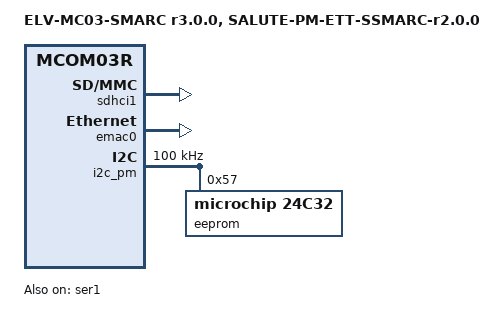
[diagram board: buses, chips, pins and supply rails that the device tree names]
// SPDX-License-Identifier: GPL-2.0+
// Copyright 2026 RnD Center "ELVEES", JSC

/dts-v1/;

#include "mcom03r-elvmc03smarc-r3.0.0.dtsi"

/ {	model = "ELV-MC03-SMARC r3.0.0, SALUTE-PM-ETT-SSMARC-r2.0.0";
	compatible = "elvees,elvmc03smarc-r3.0.0-salute-pm-ett-ssmarc-r2.0.0",
		     "elvees,elvmc03smarc-salute-pm-ett-ssmarc",
		     "elvees,salute-pm-ett-ssmarc-r2.0.0",
		     "elvees,salute-pm-ett-ssmarc",
		     "elvees,elvmc03smarc-r3.0.0",
		     "elvees,elvmc03smarc",
		     "elvees,mcom03r";

	chosen {
		stdout-path = "serial0:115200n8";
	};
};

/* Connected to USB Type-C Debug UART */
&ser1 {
	status = "okay";
	clock-frequency = <27920454>;
};

&sdhci1 {
	status = "okay";

	/* Disable 1.8V support
	 * Disable SDR50, SDR104 and DDR50 support
	 */
	sdhci-caps-mask = <0x7 0x4000000>;
	sdhci-caps = <0x0 0x0>;
};

&emac0 {
	status = "okay";
};

&i2c_pm {
	status = "okay";
	clock-frequency = <100000>;

	eeprom@57 {
		compatible = "microchip,24c32", "atmel,24c32";
		reg = <0x57>;
	};
};
